# EDMACC_0_TC_0 register map
Vendor: Texas Instruments
Peripheral module from a debugger description file (folder 66AK2G0x_66AK2G1x).
Registers are 32-bit, read-only, reset values left out (the file's numbers can be read two ways) unless marked. A register's access mark holds for its fields unless they carry their own. Offsets are as the file gives them; lines under a group give offsets from that group; [hi:lo] are bit positions; {n}, {i} and the like mark numbered series; 'fields as' and 'values as' point back to an identical list; <NAME> marks a mode.

## EDMACC_0_TC_0
0x00 EDMATC_PID
  [31:0] PID — TI internal data. Identifies revision of peripheral.
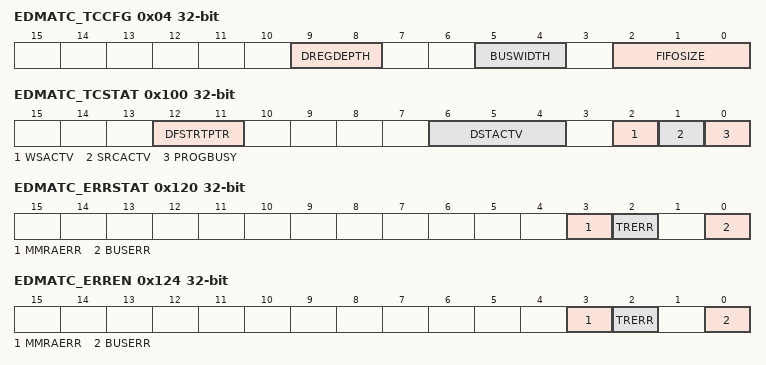
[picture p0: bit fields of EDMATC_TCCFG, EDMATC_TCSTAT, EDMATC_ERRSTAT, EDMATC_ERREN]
0x04 EDMATC_TCCFG
  [9:8] DREGDEPTH — Destination register FIFO depth parameterization.0h - 1h = Reserved 2h = 4 entry 3h = Reserved
  [5:4] BUSWIDTH — Destination register FIFO depth parameterization.0h - 1h =Reserved 2h = 128-bit 3h = 256-bit
  [2:0] FIFOSIZE — FIFO size.0h - 3h = Reserved 4h = 512-byte FIFO 5h = 1024-byte FIFO 6h - 7h = Reserved
0x100 EDMATC_TCSTAT
  [12:11] DFSTRTPTR — Destination FIFO start pointer. Represents the offset to the head entry of the destination register FIFO, in units of entries.
  [6:4] DSTACTV — Destination active state. Specifies the number of transfer requests (TRs) that are resident in the destination register FIFO at a given instant. This bit field can be primarily used for advanced debugging. Legal values are constrained by the destination register FIFO depth parameterization (DSTREGDEPTH) parameter.0h = Destination FIFO is empty. 1h = Destination FIFO contains 1 TR. 2h = Destination FIFO contains 2 TRs. 3h = Destination FIFO contains 3 TRs. 4h = Destination FIFO contains 4 TRs. (Full if DSTREGDEPTH==4) If the destination register FIFO is empty, then any TR written to Prog Set immediately transitions to the destination register FIFO. If the destination register FIFO is not empty and not full, then any TR written to Prog Set immediately transitions to the destination register FIFO set if the source active state (SRCACTV) bit is set to idle. If the destination register FIFO is full, then TRs cannot transition to the destination register FIFO. The destination register FIFO becomes not full when the TR at the head of the destination register FIFO is completed. 5h - 7h = Reserved
  [2] WSACTV — Write status active.0h = Write status is not pending. Write status has been received for all previously issued write commands. 1h = Write status is pending. Write status has not been received for all previously issued write commands.
  [1] SRCACTV — Source active state.0h = Source controller is idle. Source active register set contains a previously processed transfer request. 1h = Source controller is busy servicing a transfer request.
  [0] PROGBUSY — Program register set busy.0h = Program set idle and is available for programming by the EDMACC. 1h = Program set busy.
0x120 EDMATC_ERRSTAT
  [3] MMRAERR — MMR address error.0h = Condition is not detected 1h = User attempted to read or write to an invalid address in configuration memory map.
  [2] TRERR — Transfer request (TR) error event.0h = Condition is not detected. 1h = TR detected that violates constant addressing mode transfer (SAM or DAM is set) alignment rules or has ACNT or BCNT == 0
  [0] BUSERR — Bus error event.0h = Condition is not detected. 1h = EDMATC has detected an error at source or destination address. Error information can be read from the error details register (
0x124 EDMATC_ERREN access per field
  [3] MMRAERR rw — Interrupt enable for MMR address error (MMRAERR).0h = MMRAERR is disabled. 1h = MMRAERR is enabled and contributes to the state of EDMATC error interrupt generation
  [2] TRERR rw — Interrupt enable for transfer request error (TRERR).0h = TRERR is disabled. 1h = TRERR is enabled and contributes to the state of EDMATC error interrupt generation.
  [0] BUSERR rw — Bus error event.0h = BUSERR is disabled. 1h = BUSERR is enabled and contributes to the state of EDMATC error interrupt generation.
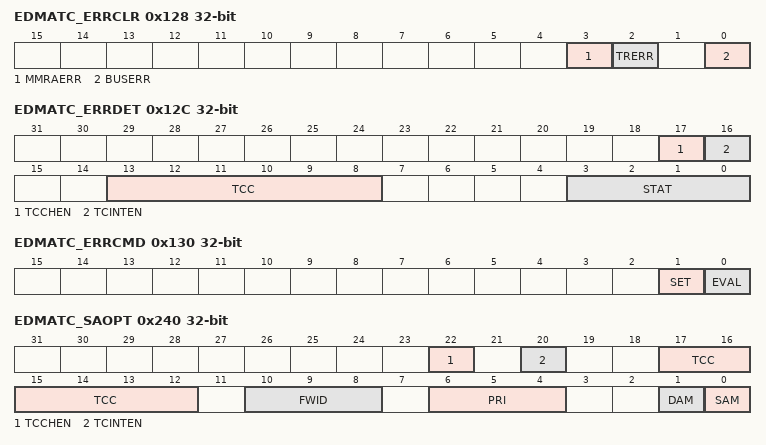
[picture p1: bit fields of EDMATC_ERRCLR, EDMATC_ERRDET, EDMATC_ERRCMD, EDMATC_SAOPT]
0x128 EDMATC_ERRCLR access per field
  [3] MMRAERR wo — Interrupt enable clear for the MMRAERR bit in the error status register (EDMATC_ERRSTAT). 0h = No effect. 1h = Clears the MMRAERR bit in
  [2] TRERR wo — Interrupt enable clear for the TRERR bit in the error status register (EDMATC_ERRSTAT). 0h = No effect. 1h = Clears the TRERR bit in
  [0] BUSERR wo — Interrupt clear for the BUSERR bit in the error status register (EDMATC_ERRSTAT). 0h = No effect. 1h = Clears the BUSERR bit in
0x12C EDMATC_ERRDET
  [17] TCCHEN — Transfer completion chaining enable. Contains the TCCHEN value in the channel options parameter (OPT) programmed by the channel controller for the read or write transaction that resulted in an error.
  [16] TCINTEN — Transfer completion interrupt enable. Contains the TCINTEN value in the channel options parameter (OPT) programmed by the channel controller for the read or write transaction that resulted in an error.
  [13:8] TCC — Transfer complete code. Contains the TCC value in the channel options parameter (OPT) programmed by the channel controller for the read or write transaction that resulted in an error.
  [3:0] STAT — Transaction status. Stores the nonzero status/error code that was detected on the read status or write status bus. If read status and write status are returned on the same cycle, then the EDMATC chooses nonzero version. If both are nonzero, then the write status is treated as higher priority.0h = No error 1h - 7h = Read error 8h - Fh = Write error
0x130 EDMATC_ERRCMD access per field
  [1] SET wo — Always write 0 to this bit; writes of 1 to this bit are not supported and attempts to do so may result in undefined behavior.
  [0] EVAL wo — Error evaluate.0h = No effect. 1h = EDMATC error line is pulsed if any of the error status register (
0x140 EDMATC_RDRATE access per field
  [2:0] RDRATE rw — Read rate. Controls the number of cycles between read commands. This is a global setting that applies to all TRs for this EDMATC.0h = Reads issued as fast as possible. 1h = 4 cycles between reads. 2h = 8 cycles between reads. 3h = 16 cycles between reads. 4h = 32 cycles between reads. 5h - 7h = Reserved
0x240 EDMATC_SAOPT access per field
  [22] TCCHEN rw — Transfer completion chaining enable.0h = Transfer complete chaining is disabled. 1h = Transfer complete chaining is enabled.
  [20] TCINTEN rw — Transfer complete interrupt enable.0h = Transfer complete interrupt is disabled. 1h = Transfer complete interrupt is enabled.
  [17:12] TCC rw — Transfer complete code. This 6-bit code is used to set the relevant bit in CER or IPR of the EDMACC module.
  [10:8] FWID rw — FIFO width. Applies if either SAM or DAM is set to constant addressing mode.0h = FIFO width is 8-bit. 1h = FIFO width is 16-bit. 2h = FIFO width is 32-bit. 3h = FIFO width is 64-bit. 4h = FIFO width is 128-bit. 5h = FIFO width is 256-bit. 6h - 7h = Reserved
  [6:4] PRI rw — Transfer priority. Reflects the values programmed in the QUEPRI register in the EDMACC.0h = Priority 0 - Highest priority 1h - 6h = Priority 1 to priority 6 7h = Priority 7 - Lowest priority
  [1] DAM rw — Destination address mode within an array.0h = Increment (INCR) mode. Destination addressing within an array increments. 1h = Constant addressing (CONST) mode. Destination addressing within an array wraps around upon reaching FIFO width.
  [0] SAM rw — Source address mode within an array.0h = Increment (INCR) mode. Source addressing within an array increments. 1h = Constant addressing (CONST) mode. Source addressing within an array wraps around upon reaching FIFO width.
0x244 EDMATC_SASRC
  [31:0] SADDR — Source address for program register set. EDMATC updates value according to source addressing mode (SAM bit in the source active options register,EDMATC_SAOPT). Value = 0-FFFF FFFFh
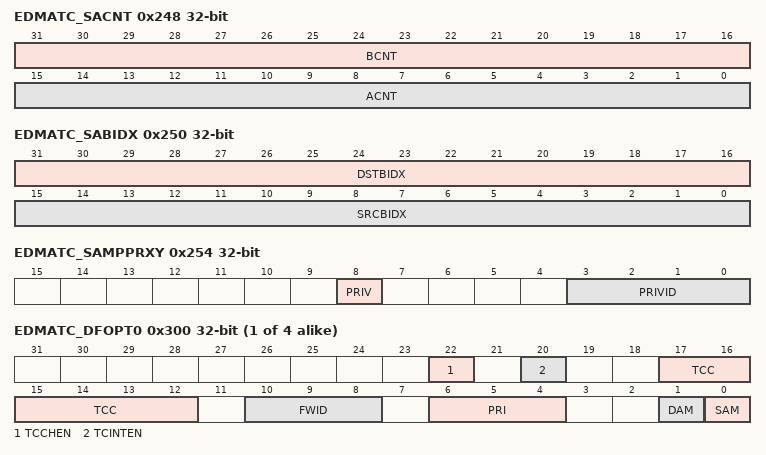
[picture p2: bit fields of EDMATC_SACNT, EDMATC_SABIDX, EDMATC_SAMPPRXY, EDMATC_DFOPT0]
0x248 EDMATC_SACNT
  [31:16] BCNT — B dimension count. Number of arrays to be transferred, where each array is ACNT in length. It is decremented after each read command appropriately. Represents the amount of data remaining to be read. It should be 0 when transfer request (TR) is complete. Value = 0-FFFFh
  [15:0] ACNT — A dimension count. Number of bytes to be transferred in first dimension. It is decremented after each read command appropriately. Represents the amount of data remaining to be read. It should be 0 when transfer request (TR) is complete. Value = 0-FFFFh
0x24C EDMATC_SADST
  [31:0] DADDR — Always reads as 0.
0x250 EDMATC_SABIDX
  [31:16] DSTBIDX — B-Index offset between destination arrays. Represents the offset in bytes between the starting address of each destination. Always reads as 0.
  [15:0] SRCBIDX — B-Index offset between source arrays. Represents the offset in bytes between the starting address of each source array. Value = 0-FFFFh
0x254 EDMATC_SAMPPRXY
  [8] PRIV — Privilege level. The privilege level used by the host to set up the parameter entry in the channel controller. This field is set up when the associated TR is submitted to the EDMATC.The privilege ID is used while issuing read and write command to the target endpoints so that the target endpoints can perform memory protection checks based on the PRIV of the host that set up the DMA transaction. 0h = User-level privilege 1h = Supervisor-level privilege
  [3:0] PRIVID — Privilege ID. This contains the privilege ID of the host that set up the parameter entry in the channel controller. This field is set up when the associated TR is submitted to the EDMATC.This PRIVID value is used while issuing read and write commands to the target endpoints so that the target endpoints can perform memory protection checks based on the PRIVID of the host that set up the DMA transaction.
0x258 EDMATC_SACNTRLD
  [15:0] ACNTRLD — A-count reload value. Represents the originally programmed value of ACNT. The reload value is used to reinitialize ACNT after each array is serviced. Value = 0-FFFFh
0x25C EDMATC_SASRCBREF
  [31:0] SADDRBREF — Source address B-reference. Represents the starting address for the array currently being read. Value = 0-FFFF FFFFh
0x260 EDMATC_SADSTBREF
  [31:0] DADDRBREF — Always reads as 0.
0x280 EDMATC_DFCNTRLD
  fields as EDMATC_SACNTRLD
0x284 EDMATC_DFSRCBREF
  [31:0] SADDRBREF — Not Applicable. Always read as 0.
0x288 EDMATC_DFDSTBREF
  [31:0] DADDRBREF — Destination address reference for the destination FIFO register set. Represents the starting address for the array currently being written. Value =0-FFFF FFFFh
{0x300+0x40*i} EDMATC_DFOPT{i} access per field (i=0..3)
  [22] TCCHEN rw — Transfer completion chaining enable.0h = Transfer complete chaining is disabled. 1h = Transfer complete chaining is enabled.
  [20] TCINTEN rw — Transfer complete interrupt enable.0h = Transfer complete interrupt is disabled. 1h = Transfer complete interrupt is enabled.
  [17:12] TCC rw — Transfer complete code. This 6-bit code is used to set the relevant bit in CER or IPR of the EDMACC module.
  [10:8] FWID rw — FIFO width. Applies if either SAM or DAM is set to constant addressing mode.0h = FIFO width is 8-bit. 1h = FIFO width is 16-bit. 2h = FIFO width is 32-bit. 3h = FIFO width is 64-bit. 4h = FIFO width is 128-bit. 5h = FIFO width is 256-bit. 6h - 7h = Reserved
  [6:4] PRI rw — Transfer priority.0h = Priority 0 - Highest priority 1h - 6h = Priority 1 to priority 6 7h = Priority 7 - Lowest priority
  [1] DAM rw — Destination address mode within an array.0h = Increment (INCR) mode. Destination addressing within an array increments. 1h = Constant addressing (CONST) mode. Destination addressing within an array wraps around upon reaching FIFO width.
  [0] SAM rw — Source address mode within an array.0h = Increment (INCR) mode. Source addressing within an array increments. 1h = Constant addressing (CONST) mode. Source addressing within an array wraps around upon reaching FIFO width.
{0x304+0x40*i} EDMATC_DFSRC{i} (i=0..3)
  [31:0] SADDR — Always read as 0.
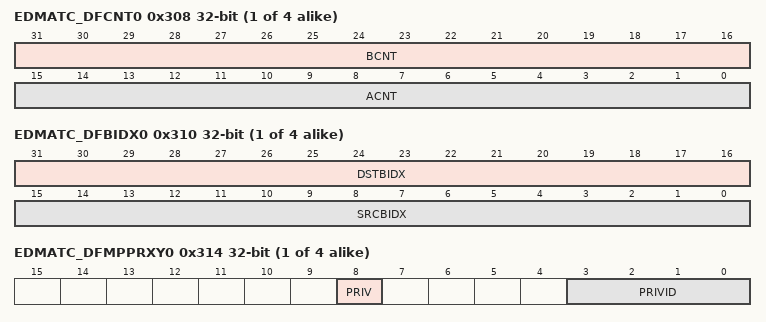
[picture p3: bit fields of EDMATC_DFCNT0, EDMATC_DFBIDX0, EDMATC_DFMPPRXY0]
{0x308+0x40*i} EDMATC_DFCNT{i} (i=0..3)
  [31:16] BCNT — B-dimension count. Number of arrays to be transferred, where each array is ACNT in length. Count/count remaining for destination register set. Represents the amount of data remaining to be written. Value = 0-FFFFh
  [15:0] ACNT — A-dimension count. Number of bytes to be transferred in first dimension count/count remaining for destination register set. Represents the amount of data remaining to be written. Value = 0-FFFFh
{0x30C+0x40*i} EDMATC_DFDST{i} (i=0..3)
  [31:0] DADDR — Destination address for the destination FIFO register set. When a transfer request (TR) is complete, the final value should be the address of the last write command issued.
{0x310+0x40*i} EDMATC_DFBIDX{i} (i=0..3)
  [31:16] DSTBIDX — B-Index offset between destination arrays. Represents the offset in bytes between the starting address of each destination. Value = 0-FFFFh
  [15:0] SRCBIDX — Always reads as 0.
{0x314+0x40*i} EDMATC_DFMPPRXY{i} (i=0..3)
  [8] PRIV — Privilege level. This contains the Privilege level used by the EDMA programmer to set up the parameter entry in the channel controller. This field is set up when the associated TR is submitted to the EDMATC.The privilege ID is used while issuing read and write commands to the target endpoints so that the target endpoints can perform memory protection checks based on the PRIV of the host that set up the DMA transaction. 0h = User-level privilege 1h = Supervisor-level privilege
  [3:0] PRIVID — Privilege ID. This contains the Privilege ID of the EDMA programmer that set up the parameter entry in the channel controller. This field is set up when the associated TR is submitted to the EDMATC.This PRIVID value is used while issuing read and write commands to the target endpoints so that the target endpoints can perform memory protection checks based on the PRIVID of the host that set up the DMA transaction.
